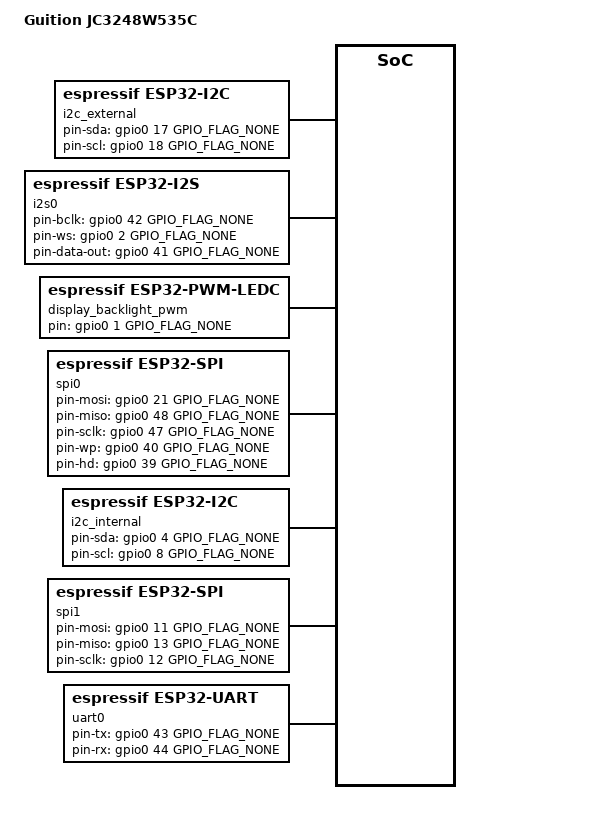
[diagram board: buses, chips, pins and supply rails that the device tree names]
/dts-v1/;

#include <tactility/bindings/root.h>
#include <tactility/bindings/esp32_ble.h>
#include <tactility/bindings/esp32_wifi_pinned.h>
#include <tactility/bindings/esp32_gpio.h>
#include <tactility/bindings/esp32_i2c.h>
#include <tactility/bindings/esp32_i2s.h>
#include <tactility/bindings/esp32_spi.h>
#include <tactility/bindings/esp32_uart.h>
#include <tactility/bindings/esp32_sdspi.h>
#include <tactility/bindings/esp32_pwm_ledc.h>
#include <tactility/bindings/pwm_backlight.h>
#include <bindings/dummy_i2s_amp.h>
#include <bindings/axs15231b_display.h>
#include <bindings/axs15231b_touch.h>

/ {
	compatible = "root";
	model = "Guition JC3248W535C";

	wifi0 {
		compatible = "espressif,esp32-wifi-pinned";
		status = "disabled";
	};

	ble0 {
		compatible = "espressif,esp32-ble";
		status = "disabled";
	};

	gpio0 {
		compatible = "espressif,esp32-gpio";
		gpio-count = <49>;
	};

	i2c_external: i2c1 {
		compatible = "espressif,esp32-i2c";
		port = <I2C_NUM_1>;
		clock-frequency = <400000>;
		pin-sda = <&gpio0 17 GPIO_FLAG_NONE>;
		pin-scl = <&gpio0 18 GPIO_FLAG_NONE>;
	};

	i2s0 {
		compatible = "espressif,esp32-i2s";
		port = <I2S_NUM_0>;
		pin-bclk = <&gpio0 42 GPIO_FLAG_NONE>;
		pin-ws = <&gpio0 2 GPIO_FLAG_NONE>;
		pin-data-out = <&gpio0 41 GPIO_FLAG_NONE>;
	};

	speaker0 {
		compatible = "nsiway,ns4168";
		i2s = <&i2s0>;
	};

	display_backlight_pwm {
		compatible = "espressif,esp32-pwm-ledc";
		pin = <&gpio0 1 GPIO_FLAG_NONE>;
		period-ns = <25000>;
		ledc-timer = <0>;
		ledc-channel = <0>;
		// Matches the deprecated HAL's old PwmBacklight driver, which hardcoded 8-bit duty
		// resolution (the binding's own default is 10-bit).
		duty-resolution = <8>;
	};

	display_backlight {
		compatible = "pwm-backlight";
		// Off by default so display power-on won't show the screen from before the last power loss.
		// The display backlight is turned on during the boot process.
		status = "disabled";
		pwm = <&display_backlight_pwm>;
	};

	spi0 {
		compatible = "espressif,esp32-spi";
		host = <SPI2_HOST>;
		cs-gpios = <&gpio0 45 GPIO_FLAG_NONE>;
		pin-mosi = <&gpio0 21 GPIO_FLAG_NONE>;
		pin-miso = <&gpio0 48 GPIO_FLAG_NONE>;
		pin-sclk = <&gpio0 47 GPIO_FLAG_NONE>;
		pin-wp = <&gpio0 40 GPIO_FLAG_NONE>;
		pin-hd = <&gpio0 39 GPIO_FLAG_NONE>;

		display@0 {
			compatible = "axs,axs15231b";
			horizontal-resolution = <320>;
			vertical-resolution = <480>;
			pin-te = <&gpio0 38 GPIO_FLAG_NONE>;
			backlight = <&display_backlight>;
			// Confirmed on real hardware: a sub-region draw desyncs this panel's row
			// auto-increment counter (no QSPI row-address command exists to resync it),
			// producing a sheared/doubled image - see requires-full-frame's binding doc.
			requires-full-frame;

			// Vendor bring-up sequence, carried over unchanged from the deprecated HAL's old
			// Axs15231bDisplay.cpp. Framing is [cmd, data-length, delay-ms, data-length bytes of
			// data...] - see axs15231b-module's init-sequence binding property for the encoding.
			init-sequence = [
				0xBB 8 0    0x00 0x00 0x00 0x00 0x00 0x00 0x5A 0xA5
				0xA0 17 0   0xC0 0x10 0x00 0x02 0x00 0x00 0x04 0x3F 0x20 0x05 0x3F 0x3F 0x00 0x00 0x00 0x00 0x00
				0xA2 31 0   0x30 0x3C 0x24 0x14 0xD0 0x20 0xFF 0xE0 0x40 0x19 0x80 0x80 0x80 0x20 0xf9 0x10 0x02 0xff 0xff 0xF0 0x90 0x01 0x32 0xA0 0x91 0xE0 0x20 0x7F 0xFF 0x00 0x5A
				0xD0 30 0   0xE0 0x40 0x51 0x24 0x08 0x05 0x10 0x01 0x20 0x15 0x42 0xC2 0x22 0x22 0xAA 0x03 0x10 0x12 0x60 0x14 0x1E 0x51 0x15 0x00 0x8A 0x20 0x00 0x03 0x3A 0x12
				0xA3 22 0   0xA0 0x06 0xAa 0x00 0x08 0x02 0x0A 0x04 0x04 0x04 0x04 0x04 0x04 0x04 0x04 0x04 0x04 0x04 0x04 0x00 0x55 0x55
				0xC1 30 0   0x31 0x04 0x02 0x02 0x71 0x05 0x24 0x55 0x02 0x00 0x41 0x00 0x53 0xFF 0xFF 0xFF 0x4F 0x52 0x00 0x4F 0x52 0x00 0x45 0x3B 0x0B 0x02 0x0d 0x00 0xFF 0x40
				0xC3 11 0   0x00 0x00 0x00 0x50 0x03 0x00 0x00 0x00 0x01 0x80 0x01
				0xC4 29 0   0x00 0x24 0x33 0x80 0x00 0xea 0x64 0x32 0xC8 0x64 0xC8 0x32 0x90 0x90 0x11 0x06 0xDC 0xFA 0x00 0x00 0x80 0xFE 0x10 0x10 0x00 0x0A 0x0A 0x44 0x50
				0xC5 23 0   0x18 0x00 0x00 0x03 0xFE 0x3A 0x4A 0x20 0x30 0x10 0x88 0xDE 0x0D 0x08 0x0F 0x0F 0x01 0x3A 0x4A 0x20 0x10 0x10 0x00
				0xC6 20 0   0x05 0x0A 0x05 0x0A 0x00 0xE0 0x2E 0x0B 0x12 0x22 0x12 0x22 0x01 0x03 0x00 0x3F 0x6A 0x18 0xC8 0x22
				0xC7 20 0   0x50 0x32 0x28 0x00 0xa2 0x80 0x8f 0x00 0x80 0xff 0x07 0x11 0x9c 0x67 0xff 0x24 0x0c 0x0d 0x0e 0x0f
				0xC9 4 0    0x33 0x44 0x44 0x01
				0xCF 27 0   0x2C 0x1E 0x88 0x58 0x13 0x18 0x56 0x18 0x1E 0x68 0x88 0x00 0x65 0x09 0x22 0xC4 0x0C 0x77 0x22 0x44 0xAA 0x55 0x08 0x08 0x12 0xA0 0x08
				0xD5 30 0   0x40 0x8E 0x8D 0x01 0x35 0x04 0x92 0x74 0x04 0x92 0x74 0x04 0x08 0x6A 0x04 0x46 0x03 0x03 0x03 0x03 0x82 0x01 0x03 0x00 0xE0 0x51 0xA1 0x00 0x00 0x00
				0xD6 30 0   0x10 0x32 0x54 0x76 0x98 0xBA 0xDC 0xFE 0x93 0x00 0x01 0x83 0x07 0x07 0x00 0x07 0x07 0x00 0x03 0x03 0x03 0x03 0x03 0x03 0x00 0x84 0x00 0x20 0x01 0x00
				0xD7 19 0   0x03 0x01 0x0b 0x09 0x0f 0x0d 0x1E 0x1F 0x18 0x1d 0x1f 0x19 0x40 0x8E 0x04 0x00 0x20 0xA0 0x1F
				0xD8 12 0   0x02 0x00 0x0a 0x08 0x0e 0x0c 0x1E 0x1F 0x18 0x1d 0x1f 0x19
				0xD9 12 0   0x1F 0x1F 0x1F 0x1F 0x1F 0x1F 0x1F 0x1F 0x1F 0x1F 0x1F 0x1F
				0xDD 12 0   0x1F 0x1F 0x1F 0x1F 0x1F 0x1F 0x1F 0x1F 0x1F 0x1F 0x1F 0x1F
				0xDF 8 0    0x44 0x73 0x4B 0x69 0x00 0x0A 0x02 0x90
				0xE0 17 0   0x3B 0x28 0x10 0x16 0x0c 0x06 0x11 0x28 0x5c 0x21 0x0D 0x35 0x13 0x2C 0x33 0x28 0x0D
				0xE1 17 0   0x37 0x28 0x10 0x16 0x0b 0x06 0x11 0x28 0x5C 0x21 0x0D 0x35 0x14 0x2C 0x33 0x28 0x0F
				0xE2 17 0   0x3B 0x07 0x12 0x18 0x0E 0x0D 0x17 0x35 0x44 0x32 0x0C 0x14 0x14 0x36 0x3A 0x2F 0x0D
				0xE3 17 0   0x37 0x07 0x12 0x18 0x0E 0x0D 0x17 0x35 0x44 0x32 0x0C 0x14 0x14 0x36 0x32 0x2F 0x0F
				0xE4 17 0   0x3B 0x07 0x12 0x18 0x0E 0x0D 0x17 0x39 0x44 0x2E 0x0C 0x14 0x14 0x36 0x3A 0x2F 0x0D
				0xE5 17 0   0x37 0x07 0x12 0x18 0x0E 0x0D 0x17 0x39 0x44 0x2E 0x0C 0x14 0x14 0x36 0x3A 0x2F 0x0F
				0xA4 16 0   0x85 0x85 0x95 0x82 0xAF 0xAA 0xAA 0x80 0x10 0x30 0x40 0x40 0x20 0xFF 0x60 0x30
				0xA4 4 0    0x85 0x85 0x95 0x85
				0xBB 8 0    0x00 0x00 0x00 0x00 0x00 0x00 0x00 0x00
				0x13 0 0
				0x35 1 0    0x00
				0x11 0 120
				0x2C 4 0    0x00 0x00 0x00 0x00
			];
		};
	};

	// Declared (and thus started) after display@0 above, not before: the display and touch
	// sides of this chip share the same silicon, and the deprecated HAL's old Hal.cpp always
	// started the display first, then the touch device second. Starting touch first (as an
	// earlier version of this devicetree did) let touch's I2C handshake succeed initially, but
	// the display's own reset/init sequence running afterward then reset the whole chip and
	// left the touch interface unresponsive - confirmed on real hardware (I2C writes started
	// failing consistently right after display bring-up completed).
	i2c_internal: i2c0 {
		compatible = "espressif,esp32-i2c";
		port = <I2C_NUM_0>;
		clock-frequency = <400000>;
		pin-sda = <&gpio0 4 GPIO_FLAG_NONE>;
		pin-scl = <&gpio0 8 GPIO_FLAG_NONE>;

		touch {
			compatible = "axs,axs15231b-touch";
			reg = <0x3B>;
			x-max = <320>;
			y-max = <480>;
		};
	};

	spi1 {
		compatible = "espressif,esp32-spi";
		host = <SPI3_HOST>;
		cs-gpios = <&gpio0 10 GPIO_FLAG_NONE>;
		pin-mosi = <&gpio0 11 GPIO_FLAG_NONE>;
		pin-miso = <&gpio0 13 GPIO_FLAG_NONE>;
		pin-sclk = <&gpio0 12 GPIO_FLAG_NONE>;
	
		sdcard@0 {
			compatible = "espressif,esp32-sdspi";
			frequency-khz = <20000>;
		};
	};

	// P1 header
	uart0 {
		compatible = "espressif,esp32-uart";
		port = <UART_NUM_0>;
		pin-tx = <&gpio0 43 GPIO_FLAG_NONE>;
		pin-rx = <&gpio0 44 GPIO_FLAG_NONE>;
	};
};
